# MSP430F2619 register map
Vendor: msp430gen; File version: v0.4.0
Registers are 8-bit, read-write, reset 0x0 unless marked. A register's access mark holds for its fields unless they carry their own. Offsets are from the block's base; [hi:lo] are bit positions; {n}, {i} and the like mark numbered series.

## USCI_B0_SPI_MODE
Base 0x00000068
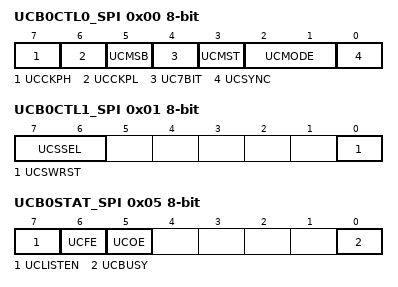
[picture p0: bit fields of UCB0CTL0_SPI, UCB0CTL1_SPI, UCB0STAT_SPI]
0x00 UCB0CTL0_SPI — USCI B0 Control Register 0
  [7] UCCKPH — Sync. Mode: Clock Phase
  [6] UCCKPL — Sync. Mode: Clock Polarity
  [5] UCMSB — Sync. Mode: MSB first 0:LSB / 1:MSB
  [4] UC7BIT — Sync. Mode: Data Bits 0:8-bits / 1:7-bits
  [3] UCMST — Sync. Mode: Master Select
  [2:1] UCMODE — Sync. Mode: USCI Mode 1
    {v}=Sync. Mode: USCI Mode: {v} (v=0..3)
  [0] UCSYNC — Sync-Mode 0:UART-Mode / 1:SPI-Mode
0x01 UCB0CTL1_SPI — USCI B0 Control Register 1
  [7:6] UCSSEL — USCI 1 Clock Source Select 1
    {v}=USCI 0 Clock Source: {v} (v=0..3)
  [0] UCSWRST — USCI Software Reset
0x02 UCB0BR0_SPI — USCI B0 Baud Rate 0
0x03 UCB0BR1_SPI — USCI B0 Baud Rate 1
0x05 UCB0STAT_SPI — USCI B0 Status Register
  [7] UCLISTEN — USCI Listen mode
  [6] UCFE — USCI Frame Error Flag
  [5] UCOE — USCI Overrun Error Flag
  [0] UCBUSY — USCI Busy Flag
0x06 UCB0RXBUF_SPI — USCI B0 Receive Buffer
0x07 UCB0TXBUF_SPI — USCI B0 Transmit Buffer

## ADC12
Base 0x00000080
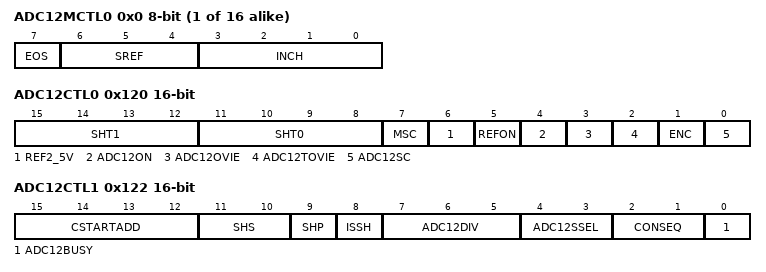
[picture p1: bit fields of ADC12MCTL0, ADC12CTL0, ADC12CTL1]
{0x0+i} ADC12MCTL{i} (i=0..15) — ADC12 Memory Control {i}
  [7] EOS — ADC12 End of Sequence
  [6:4] SREF — ADC12 Select Reference Bit 0
    {v}=ADC12 Select Reference {v} (v=0..7)
  [3:0] INCH — ADC12 Input Channel Select Bit 0
    {v}=ADC12 Input Channel {v} (v=0..15)
{0xC0+2i} ADC12MEM{i} 16-bit (i=0..15) — ADC12 Conversion Memory {i}
0x120 ADC12CTL0 16-bit — ADC12 Control 0
  [15:12] SHT1 — ADC12 Sample Hold 0 Select 0
    {v}=ADC12 Sample Hold 1 Select Bit: {v} (v=0..15)
  [11:8] SHT0 — ADC12 Sample Hold 0 Select 0
    {v}=ADC12 Sample Hold 0 Select Bit: {v} (v=0..15)
  [7] MSC — ADC12 Multiple SampleConversion
  [6] REF2_5V — ADC12 Ref 0:1.5V / 1:2.5V
  [5] REFON — ADC12 Reference on
  [4] ADC12ON — ADC12 On/enable
  [3] ADC12OVIE — ADC12 Overflow interrupt enable
  [2] ADC12TOVIE — ADC12 Timer Overflow interrupt enable
  [1] ENC — ADC12 Enable Conversion
  [0] ADC12SC — ADC12 Start Conversion
0x122 ADC12CTL1 16-bit — ADC12 Control 1
  [15:12] CSTARTADD — ADC12 Conversion Start Address 0
    {v}=ADC12 Conversion Start Address: {v} (v=0..15)
  [11:10] SHS — ADC12 Sample/Hold Source 0
    {v}=ADC12 Sample/Hold Source: {v} (v=0..3)
  [9] SHP — ADC12 Sample/Hold Pulse Mode
  [8] ISSH — ADC12 Invert Sample Hold Signal
  [7:5] ADC12DIV — ADC12 Clock Divider Select 0
    {v}=ADC12 Clock Divider Select: {v} (v=0..7)
  [4:3] ADC12SSEL — ADC12 Clock Source Select 0
    {v}=ADC12 Clock Source Select: {v} (v=0..3)
  [2:1] CONSEQ — ADC12 Conversion Sequence Select 0
    {v}=ADC12 Conversion Sequence Select: {v} (v=0..3)
  [0] ADC12BUSY
0x124 ADC12IFG 16-bit — ADC12 Interrupt Flag
0x126 ADC12IE 16-bit — ADC12 Interrupt Enable
0x128 ADC12IV 16-bit — ADC12 Interrupt Vector Word

## USCI_A1_UART_MODE
Base 0x000000CC
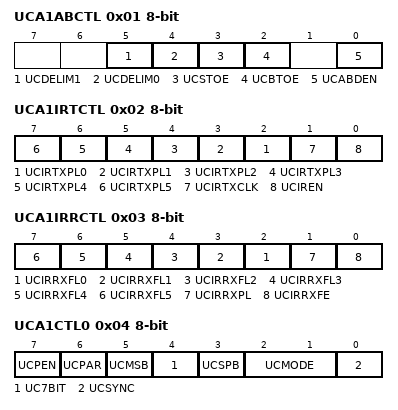
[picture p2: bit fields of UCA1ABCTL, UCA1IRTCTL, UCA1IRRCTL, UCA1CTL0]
0x01 UCA1ABCTL — USCI A1 LIN Control
  [5] UCDELIM1 — Break Sync Delimiter 1
  [4] UCDELIM0 — Break Sync Delimiter 0
  [3] UCSTOE — Sync-Field Timeout error
  [2] UCBTOE — Break Timeout error
  [0] UCABDEN — Auto Baud Rate detect enable
0x02 UCA1IRTCTL — USCI A1 IrDA Transmit Control
  [n+2] UCIRTXPL{n} (n=0..5) — IRDA Transmit Pulse Length {n}
  [1] UCIRTXCLK — IRDA Transmit Pulse Clock Select
  [0] UCIREN — IRDA Encoder/Decoder enable
0x03 UCA1IRRCTL — USCI A1 IrDA Receive Control
  [n+2] UCIRRXFL{n} (n=0..5) — IRDA Receive Filter Length {n}
  [1] UCIRRXPL — IRDA Receive Input Polarity
  [0] UCIRRXFE — IRDA Receive Filter enable
0x04 UCA1CTL0 — USCI A1 Control Register 0
  [7] UCPEN — Async. Mode: Parity enable
  [6] UCPAR — Async. Mode: Parity 0:odd / 1:even
  [5] UCMSB — Async. Mode: MSB first 0:LSB / 1:MSB
  [4] UC7BIT — Async. Mode: Data Bits 0:8-bits / 1:7-bits
  [3] UCSPB — Async. Mode: Stop Bits 0:one / 1: two
  [2:1] UCMODE — Async. Mode: USCI Mode 1
    {v}=Sync. Mode: USCI Mode: {v} (v=0..3)
  [0] UCSYNC — Sync-Mode 0:UART-Mode / 1:SPI-Mode
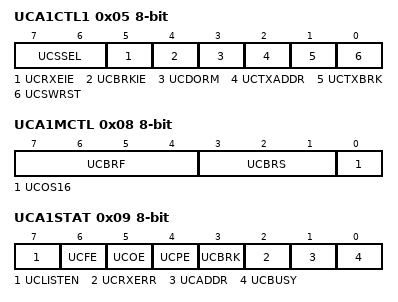
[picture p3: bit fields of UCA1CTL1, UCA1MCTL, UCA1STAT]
0x05 UCA1CTL1 — USCI A1 Control Register 1
  [7:6] UCSSEL — USCI 0 Clock Source Select 1
    {v}=USCI 0 Clock Source: {v} (v=0..3)
  [5] UCRXEIE — RX Error interrupt enable
  [4] UCBRKIE — Break interrupt enable
  [3] UCDORM — Dormant (Sleep) Mode
  [2] UCTXADDR — Send next Data as Address
  [1] UCTXBRK — Send next Data as Break
  [0] UCSWRST — USCI Software Reset
0x06 UCA1BR0 — USCI A1 Baud Rate 0
0x07 UCA1BR1 — USCI A1 Baud Rate 1
0x08 UCA1MCTL — USCI A1 Modulation Control
  [7:4] UCBRF — USCI First Stage Modulation Select 3
    {v}=USCI First Stage Modulation: {v} (v=0..9); 10=USCI First Stage Modulation: A; 11=USCI First Stage Modulation: B; 12=USCI First Stage Modulation: C; 13=USCI First Stage Modulation: D; 14=USCI First Stage Modulation: E; 15=USCI First Stage Modulation: F
  [3:1] UCBRS — USCI Second Stage Modulation Select 2
    {v}=USCI Second Stage Modulation: {v} (v=0..7)
  [0] UCOS16 — USCI 16-times Oversampling enable
0x09 UCA1STAT — USCI A1 Status Register
  [7] UCLISTEN — USCI Listen mode
  [6] UCFE — USCI Frame Error Flag
  [5] UCOE — USCI Overrun Error Flag
  [4] UCPE — USCI Parity Error Flag
  [3] UCBRK — USCI Break received
  [2] UCRXERR — USCI RX Error Flag
  [1] UCADDR — USCI Address received Flag
  [0] UCBUSY — USCI Busy Flag
0x0A UCA1RXBUF — USCI A1 Receive Buffer
0x0B UCA1TXBUF — USCI A1 Transmit Buffer
